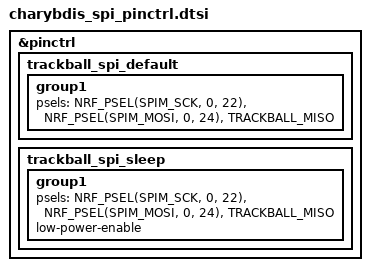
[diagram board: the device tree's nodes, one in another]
&pinctrl {
    trackball_spi_default: trackball_spi_default {
        group1 {
            psels = <NRF_PSEL(SPIM_SCK, 0, 22)>,
                    <NRF_PSEL(SPIM_MOSI, 0, 24)>,
                    <TRACKBALL_MISO>;
        };
    };

    trackball_spi_sleep: trackball_spi_sleep {
        group1 {
            psels = <NRF_PSEL(SPIM_SCK, 0, 22)>,
                    <NRF_PSEL(SPIM_MOSI, 0, 24)>,
                    <TRACKBALL_MISO>;
            low-power-enable;
        };
    };
};
